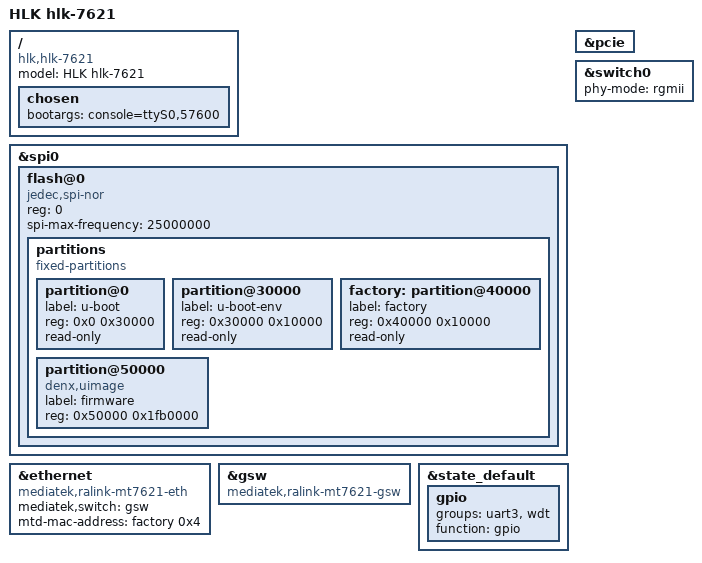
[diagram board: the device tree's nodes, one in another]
/dts-v1/;

#include "mt7621.dtsi"

#include <dt-bindings/gpio/gpio.h>
#include <dt-bindings/input/input.h>

/ {
	compatible = "hlk,hlk-7621", "mediatek,mt7621-soc";
	model = "HLK hlk-7621";

	chosen {
		bootargs = "console=ttyS0,57600";
	};

};

&spi0 {
	status = "okay";

	flash@0 {
		compatible = "jedec,spi-nor";
		reg = <0>;
		spi-max-frequency = <25000000>;

		partitions {
			compatible = "fixed-partitions";
			#address-cells = <1>;
			#size-cells = <1>;

			partition@0 {
				label = "u-boot";
				reg = <0x0 0x30000>;
				read-only;
			};

			partition@30000 {
				label = "u-boot-env";
				reg = <0x30000 0x10000>;
				read-only;
			};

			factory: partition@40000 {
				label = "factory";
				reg = <0x40000 0x10000>;
				read-only;
			};

			partition@50000 {
				compatible = "denx,uimage";
				label = "firmware";
				reg = <0x50000 0x1fb0000>;
			};
		};
	};
};

&pcie {
	status = "okay";
};

&ethernet {
	compatible = "mediatek,ralink-mt7621-eth";
	mediatek,switch = <&gsw>;
	mtd-mac-address = <&factory 0x4>;
};

&switch0 {
	/delete-property/ compatible;
	phy-mode = "rgmii";
};

&gsw {
	compatible = "mediatek,ralink-mt7621-gsw";
};

&state_default {
	gpio {
		groups = "uart3", "wdt";
		function = "gpio";
	};
};
